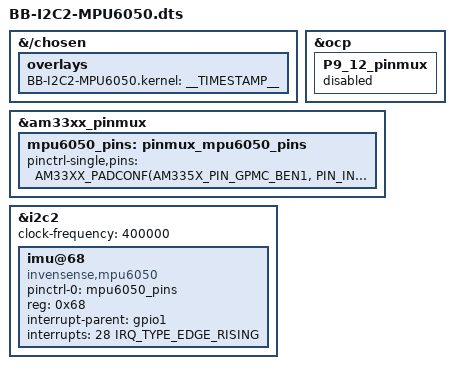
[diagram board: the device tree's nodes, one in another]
// SPDX-License-Identifier: GPL-2.0-only
/*
 * Copyright (C) 2022 Robert Nelson <robertcnelson@gmail.com>
 */

/dts-v1/;
/plugin/;

#include <dt-bindings/pinctrl/am33xx.h>
#include <dt-bindings/gpio/gpio.h>
#include <dt-bindings/interrupt-controller/irq.h>

/*
 * Helper to show loaded overlays under: /proc/device-tree/chosen/overlays/
 */
&{/chosen} {
	overlays {
		BB-I2C2-MPU6050.kernel = __TIMESTAMP__;
	};
};

/*
 * Free up the pins used by the cape from the pinmux helpers.
 */
&ocp {
	P9_12_pinmux { status = "disabled"; };
};

&am33xx_pinmux {
	mpu6050_pins: pinmux_mpu6050_pins {
		pinctrl-single,pins = <
			AM33XX_PADCONF(AM335X_PIN_GPMC_BEN1, PIN_INPUT, MUX_MODE7) /* gpio1_28 */
		>;
	};
};

&i2c2 {
	status = "okay";

	clock-frequency = <400000>;

	#address-cells = <1>;
	#size-cells = <0>;

	imu@68 {
		pinctrl-names = "default";
		pinctrl-0 = <&mpu6050_pins>;
		compatible = "invensense,mpu6050";
		reg = <0x68>;
		interrupt-parent = <&gpio1>;
		interrupts = <28 IRQ_TYPE_EDGE_RISING>;
	};
};
